# COMPUTE_CLUSTER0_ECC_AGGR_CTL register map
Vendor: Texas Instruments
Peripheral module from a debugger description file (folder J7VCL).
Registers are 32-bit, access not given, reset 0x0 unless marked. A register's access mark holds for its fields unless they carry their own. Offsets are as the file gives them; lines under a group give offsets from that group; [hi:lo] are bit positions; {n}, {i} and the like mark numbered series; 'fields as' and 'values as' point back to an identical list; <NAME> marks a mode.

## COMPUTE_CLUSTER0_ECC_AGGR_CTL
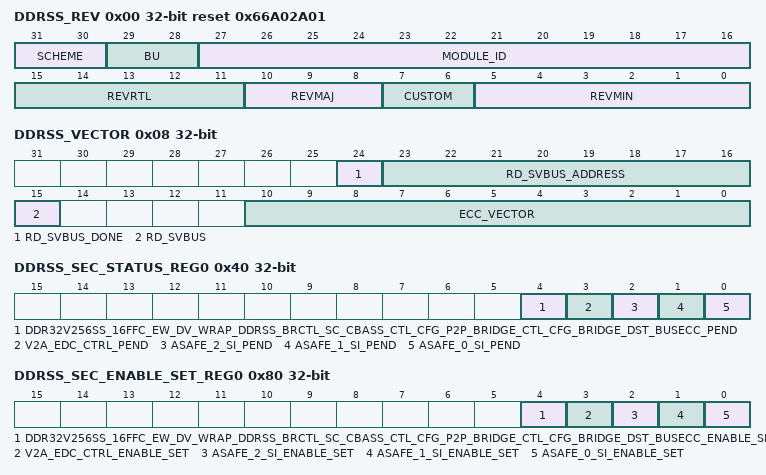
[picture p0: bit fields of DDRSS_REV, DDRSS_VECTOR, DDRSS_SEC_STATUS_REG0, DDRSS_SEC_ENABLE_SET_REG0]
0x00 DDRSS_REV ro reset 0x66A02A01 — Return to the . Revision parameters
  [31:30] SCHEME
  [29:28] BU
  [27:16] MODULE_ID
  [15:11] REVRTL — RTL version
  [10:8] REVMAJ — Major version
  [7:6] CUSTOM — Custom version
  [5:0] REVMIN — Minor version
0x08 DDRSS_VECTOR — Return to the . ECC Vector Register
  [24] RD_SVBUS_DONE — Status to indicate if read on serial VBUS is complete, write of any value will clear this bit. (access RW1C)
  [23:16] RD_SVBUS_ADDRESS rw — Read address
  [15] RD_SVBUS — Write 1 to trigger a read on the serial VBUS (access RW1S)
  [10:0] ECC_VECTOR rw — Value written to select the corresponding ECC RAM for control or status
0x0C DDRSS_STAT ro reset 0x5 — Return to the . Misc Status
  [10:0] NUM_RAMS — Indicates the number of RAMS serviced by the ECC aggregator
0x10 DDRSS_RESERVED_SVBUS_y rw — Return to the . Reference other documents that contain the ECC RAM wrapper and EDC controller serial vbus register sets. Offset = 10h + (y * 4h); where y = 0h to 7h
  [31:0] DATA — Serial VBUS register data
0x3C DDRSS_SEC_EOI_REG — Return to the . EOI Register
  [0] EOI_WR — EOI Register (access RW1S)
0x40 DDRSS_SEC_STATUS_REG0 — Return to the . Interrupt Status Register 0
  [4] DDR32V256SS_16FFC_EW_DV_WRAP_DDRSS_BRCTL_SC_CBASS_CTL_CFG_P2P_BRIDGE_CTL_CFG_BRIDGE_DST_BUSECC_PEND — Interrupt Pending Status for ddr32v256ss_16ffc_ew_dv_wrap_ddrss_brctl_sc_cbass_ctl_cfg_p2p_bridge_ctl_cfg_bridge_dst_busecc_pend (access RW1S)
  [3] V2A_EDC_CTRL_PEND — Interrupt Pending Status for v2a_edc_ctrl_pend (access RW1S)
  [2] ASAFE_2_SI_PEND — Interrupt Pending Status for asafe_2_si_pend (access RW1S)
  [1] ASAFE_1_SI_PEND — Interrupt Pending Status for asafe_1_si_pend (access RW1S)
  [0] ASAFE_0_SI_PEND — Interrupt Pending Status for asafe_0_si_pend (access RW1S)
0x80 DDRSS_SEC_ENABLE_SET_REG0 — Return to the . Interrupt Enable Set Register 0
  [4] DDR32V256SS_16FFC_EW_DV_WRAP_DDRSS_BRCTL_SC_CBASS_CTL_CFG_P2P_BRIDGE_CTL_CFG_BRIDGE_DST_BUSECC_ENABLE_SET — Interrupt Enable Set Register for ddr32v256ss_16ffc_ew_dv_wrap_ddrss_brctl_sc_cbass_ctl_cfg_p2p_bridge_ctl_cfg_bridge_dst_busecc_pend (access RW1S)
  [3] V2A_EDC_CTRL_ENABLE_SET — Interrupt Enable Set Register for v2a_edc_ctrl_pend (access RW1S)
  [2] ASAFE_2_SI_ENABLE_SET — Interrupt Enable Set Register for asafe_2_si_pend (access RW1S)
  [1] ASAFE_1_SI_ENABLE_SET — Interrupt Enable Set Register for asafe_1_si_pend (access RW1S)
  [0] ASAFE_0_SI_ENABLE_SET — Interrupt Enable Set Register for asafe_0_si_pend (access RW1S)
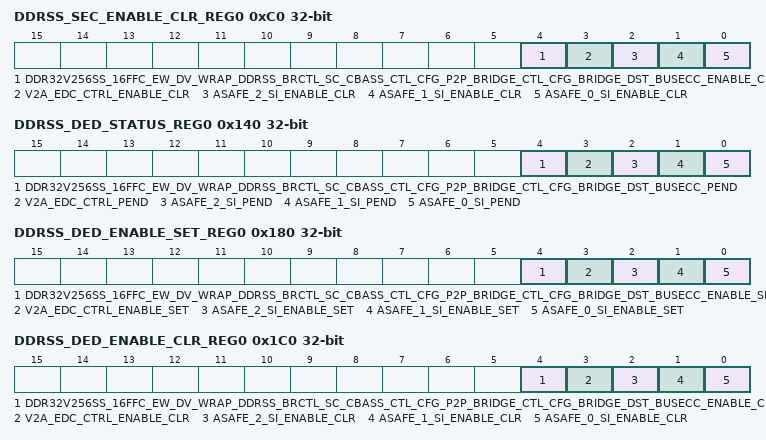
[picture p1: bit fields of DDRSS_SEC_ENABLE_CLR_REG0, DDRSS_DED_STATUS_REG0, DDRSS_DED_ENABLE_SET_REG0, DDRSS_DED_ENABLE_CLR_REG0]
0xC0 DDRSS_SEC_ENABLE_CLR_REG0 — Return to the . Interrupt Enable Clear Register 0
  [4] DDR32V256SS_16FFC_EW_DV_WRAP_DDRSS_BRCTL_SC_CBASS_CTL_CFG_P2P_BRIDGE_CTL_CFG_BRIDGE_DST_BUSECC_ENABLE_CLR — Interrupt Enable Clear Register for ddr32v256ss_16ffc_ew_dv_wrap_ddrss_brctl_sc_cbass_ctl_cfg_p2p_bridge_ctl_cfg_bridge_dst_busecc_pend (access RW1C)
  [3] V2A_EDC_CTRL_ENABLE_CLR — Interrupt Enable Clear Register for v2a_edc_ctrl_pend (access RW1C)
  [2] ASAFE_2_SI_ENABLE_CLR — Interrupt Enable Clear Register for asafe_2_si_pend (access RW1C)
  [1] ASAFE_1_SI_ENABLE_CLR — Interrupt Enable Clear Register for asafe_1_si_pend (access RW1C)
  [0] ASAFE_0_SI_ENABLE_CLR — Interrupt Enable Clear Register for asafe_0_si_pend (access RW1C)
0x13C DDRSS_DED_EOI_REG — Return to the . EOI Register
  [0] EOI_WR — EOI Register (access RW1S)
0x140 DDRSS_DED_STATUS_REG0 — Return to the . Interrupt Status Register 0
  fields as DDRSS_SEC_STATUS_REG0
0x180 DDRSS_DED_ENABLE_SET_REG0 — Return to the . Interrupt Enable Set Register 0
  fields as DDRSS_SEC_ENABLE_SET_REG0
0x1C0 DDRSS_DED_ENABLE_CLR_REG0 — Return to the . Interrupt Enable Clear Register 0
  fields as DDRSS_SEC_ENABLE_CLR_REG0
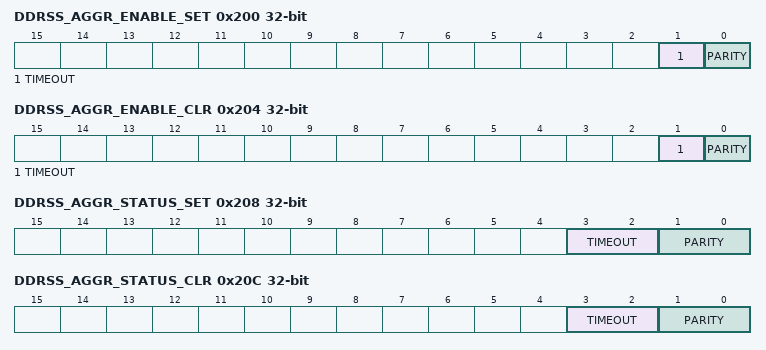
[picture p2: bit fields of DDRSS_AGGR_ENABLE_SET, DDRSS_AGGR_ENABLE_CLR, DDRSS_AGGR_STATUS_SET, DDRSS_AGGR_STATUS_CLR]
0x200 DDRSS_AGGR_ENABLE_SET — Return to the . AGGR interrupt enable set Register
  [1] TIMEOUT — interrupt enable set for svbus timeout errors (access RW1S)
  [0] PARITY — interrupt enable set for parity errors (access RW1S)
0x204 DDRSS_AGGR_ENABLE_CLR — Return to the . AGGR interrupt enable clear Register
  [1] TIMEOUT — interrupt enable clear for svbus timeout errors (access RW1C)
  [0] PARITY — interrupt enable clear for parity errors (access RW1C)
0x208 DDRSS_AGGR_STATUS_SET — Return to the . AGGR interrupt status set Register
  [3:2] TIMEOUT — interrupt status set for svbus timeout errors (access RWincr)
  [1:0] PARITY — interrupt status set for parity errors (access RWincr)
0x20C DDRSS_AGGR_STATUS_CLR — Return to the . AGGR interrupt status clear Register
  [3:2] TIMEOUT — interrupt status clear for svbus timeout errors (access RWdecr)
  [1:0] PARITY — interrupt status clear for parity errors (access RWdecr)
